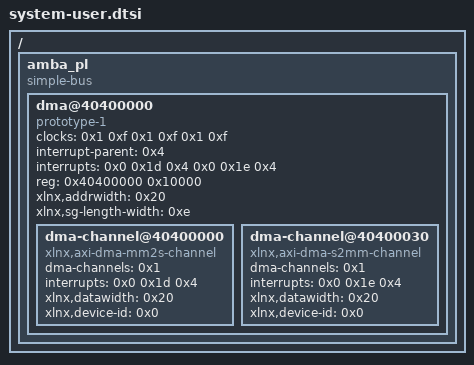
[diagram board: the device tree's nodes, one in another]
/include/ "system-conf.dtsi"
/ {
	amba_pl {
		#address-cells = <0x1>;
		#size-cells = <0x1>;
		compatible = "simple-bus";
		ranges;
		phandle = <0x38>;

		dma@40400000 {
			#dma-cells = <0x1>;
			clock-names = "s_axi_lite_aclk", "m_axi_mm2s_aclk", "m_axi_s2mm_aclk";
			clocks = <0x1 0xf 0x1 0xf 0x1 0xf>;
		//	compatible = "xlnx,axi-dma-7.1", "xlnx,axi-dma-1.00.a";
			compatible = "prototype-1";
			interrupt-names = "mm2s_introut", "s2mm_introut";
			interrupt-parent = <0x4>;
			interrupts = <0x0 0x1d 0x4 0x0 0x1e 0x4>;
			reg = <0x40400000 0x10000>;
			xlnx,addrwidth = <0x20>;
			xlnx,sg-length-width = <0xe>;
			phandle = <0x39>;

			dma-channel@40400000 {
				compatible = "xlnx,axi-dma-mm2s-channel";
				dma-channels = <0x1>;
				interrupts = <0x0 0x1d 0x4>;
				xlnx,datawidth = <0x20>;
				xlnx,device-id = <0x0>;
			};

			dma-channel@40400030 {
				compatible = "xlnx,axi-dma-s2mm-channel";
				dma-channels = <0x1>;
				interrupts = <0x0 0x1e 0x4>;
				xlnx,datawidth = <0x20>;
				xlnx,device-id = <0x0>;
			};
		};
	};
};

